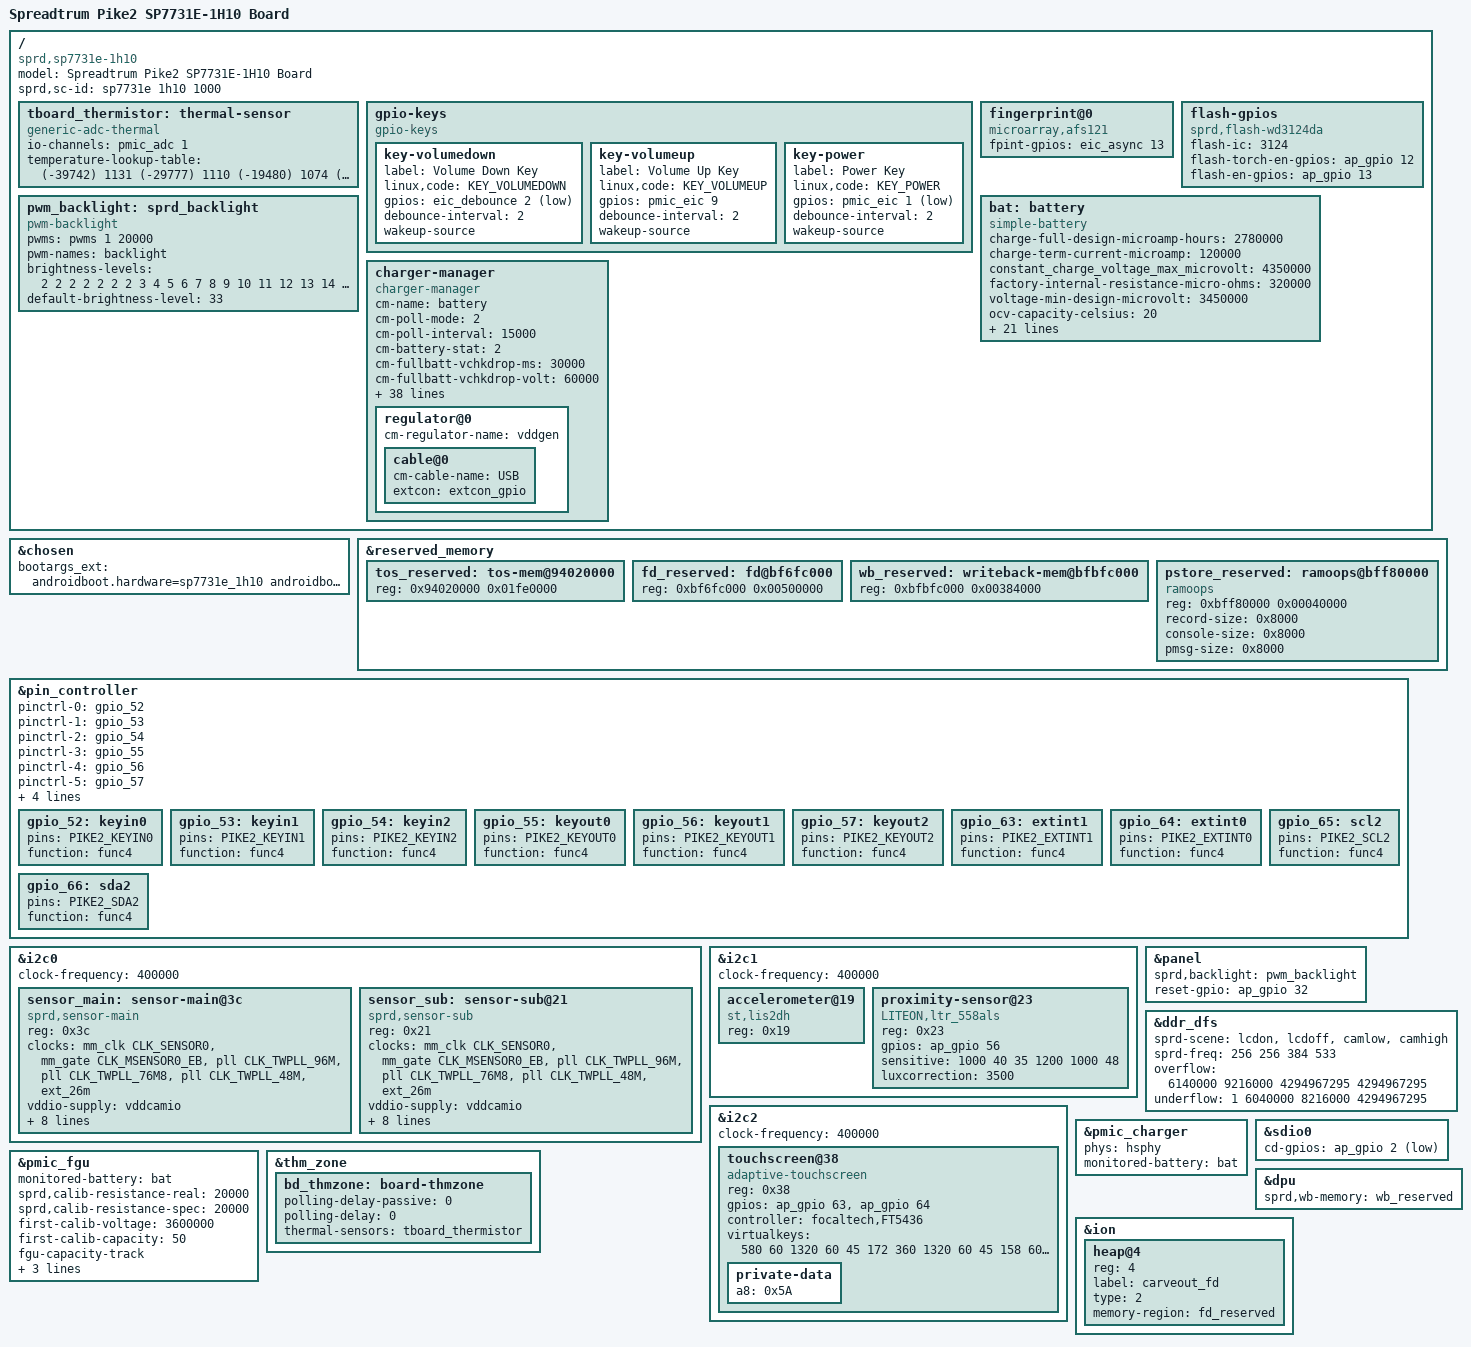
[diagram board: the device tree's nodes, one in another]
/*
 * Spreadtrum sharkle sp7731e board DTS file
 *
 * Copyright (C) 2019, Spreadtrum Communications Inc.
 *
 * This file is licensed under a dual GPLv2 or X11 license.
 */
/dts-v1/;
/plugin/;
#include <dt-bindings/input/input.h>
#include <dt-bindings/gpio/gpio.h>
#include <dt-bindings/clock/sprd,sc7731e-clk.h>
#include "lcd/lcd_ili9881c_3lane_mipi_fhd.dtsi"
#include "lcd/lcd_r61350_truly_mipi_hd_v2.dtsi"
#include "lcd/lcd_dummy_mipi.dtsi"

/ {
	model = "Spreadtrum Pike2 SP7731E-1H10 Board";

	compatible = "sprd,sp7731e-1h10", "sprd,sc7731e";

	sprd,sc-id = "sp7731e 1h10 1000";

	/*
	* When create a new node, we should use the key word __overlay__,
	* otherwise u-boot can not analyze it.
	*/
	fragment {
		target-path = "/";
		__overlay__ {

			tboard_thermistor:thermal-sensor {
				compatible = "generic-adc-thermal";
				#thermal-sensor-cells = <0>;
				io-channels = <&pmic_adc 1>;
				io-channel-names = "sensor-channel";
				temperature-lookup-table = <    (-39742) 1131
								(-29777) 1110
								(-19480) 1074
								(-4679) 983
								10110 838
								24805 654
								44922 413
								54903 316
								64895 238
								74884 178
								84883 133
								94883 100
								104880 75
								114889 57
								124872 43 >;
			};

			gpio-keys {
				compatible = "gpio-keys";

				key-volumedown {
					label = "Volume Down Key";
					linux,code = <KEY_VOLUMEDOWN>;
					gpios = <&eic_debounce 2 GPIO_ACTIVE_LOW>;
					debounce-interval = <2>;
					wakeup-source;
				};

				key-volumeup {
					label = "Volume Up Key";
					linux,code = <KEY_VOLUMEUP>;
					gpios = <&pmic_eic 9 GPIO_ACTIVE_HIGH>;
					debounce-interval = <2>;
					wakeup-source;
				};

				key-power {
					label = "Power Key";
					linux,code = <KEY_POWER>;
					gpios = <&pmic_eic 1 GPIO_ACTIVE_LOW>;
					debounce-interval = <2>;
					wakeup-source;
				};
			};

			fingerprint@0 {
				compatible = "microarray,afs121";
				fpint-gpios = <&eic_async 13 0>;
			};

			flash-gpios {
				compatible = "sprd,flash-wd3124da";
				flash-ic = <3124>;
				flash-torch-en-gpios = <&ap_gpio 12 0>;
				flash-en-gpios = <&ap_gpio 13 0>;
			};

			pwm_backlight: sprd_backlight {
				compatible = "pwm-backlight";
				pwms = <&pwms 1 20000>;
				pwm-names = "backlight";
				brightness-levels = <
								  2   2   2   2
					  2   2   2   3   4   5   6   7   8   9
					 10  11  12  13  14  15  16  17  18  19
					 20  21  22  23  24  25  26  27  28  29
					 30  31  32  33  34  35  36  37  38  39
					 40  41  42  43  44  45  46  47  48  49
					 50  51  52  53  54  55  56  57  58  59
					 60  61  62  63  64  65  66  67  68  69
					 70  71  72  73  74  75  76  77  78  79
					 80  81  82  83  84  85  86  87  88  89
					 90  91  92  93  94  95  96  97  98  99
					100 101 102 103 104 105 106 107 108 109
					110 111 112 113 114 115 116 117 118 119
					120 121 122 123 124 125 126 127 128 129
					130 131 132 133 134 135 136 137 138 139
					140 141 142 143 144 145 146 147 148 149
					150 151 152 153 154 155 156 157 158 159
					160 161 162 163 164 165 166 167 168 169
					170 171 172 173 174 175 176 177 178 179
					180 181 182 183 184 185 186 187 188 189
					190 191 192 193 194 195 196 197 198 199
					200 201 202 203 204 205 206 207 208 209
					210 211 212 213 214 215 216 217 218 219
					220 221 222 223 224 225 226 227 228 229
					230 231 232 233 234 235 236 237 238 239
					240 241 242 243 244 245 246 247 248 249
					250 251
					>;
				default-brightness-level = <33>;
			};

			bat: battery {
				compatible = "simple-battery";
				charge-full-design-microamp-hours = <2780000>;
				charge-term-current-microamp = <120000>;
				constant_charge_voltage_max_microvolt = <4350000>;
				factory-internal-resistance-micro-ohms = <320000>;
				voltage-min-design-microvolt = <3450000>;
				ocv-capacity-celsius = <20>;
				ocv-capacity-table-0 = <4330000 100>, <4249000 95>, <4189000 90>,
							<4133000 85>, <4081000 80>, <4034000 75>,
							<3991000 70>, <3953000 65>, <3910000 60>,
							<3866000 55>, <3836000 50>, <3813000 45>,
							<3795000 40>, <3782000 35>, <3774000 30>,
							<3765000 25>, <3750000 20>, <3726000 15>,
							<3687000 10>, <3658000 5>, <3400000 0>;
				voltage-temp-table = <1095000 800>, <986000 850>, <878000 900>,
							  <775000 950>, <678000 1000>, <590000 1050>,
							  <510000 1100>, <440000 1150>, <378000 1200>,
							  <324000 1250>, <278000 1300>, <238000 1350>,
							  <204000 1400>, <175000 1450>, <150000 1500>,
							  <129000 1550>, <111000 1600>, <96000 1650>;
				capacity-temp-table = <25 100>, <10 97>, <(-10) 60>;
				resistance-temp-table = <20 100>, <10 243>, <(-10) 468>;
				charge-sdp-current-microamp = <500000 500000>;
				charge-dcp-current-microamp = <1000000 1000000>;
				charge-cdp-current-microamp = <1000000 1000000>;
				charge-unknown-current-microamp = <500000 500000>;
			};

			charger-manager {
				compatible = "charger-manager";
				cm-name = "battery";
				cm-poll-mode = <2>;
				cm-poll-interval = <15000>;
				cm-battery-stat = <2>;

				cm-fullbatt-vchkdrop-ms = <30000>;
				cm-fullbatt-vchkdrop-volt = <60000>;
				cm-fullbatt-voltage = <4310000>;
				cm-fullbatt-current = <120000>;
				cm-fullbatt-capacity = <100>;

				cm-chargers = "sc2720_charger";
				cm-fuel-gauge = "sc27xx-fgu";

				/* in deci centigrade */
				cm-battery-cold = <200>;
				cm-battery-cold-in-minus;
				cm-battery-hot = <800>;
				cm-battery-temp-diff = <100>;

				/* Allow charging for 6hr */
				cm-charging-max = <18000000>;
				/* recovery charging after stop charging 45min */
				cm-discharging-max = <2700000>;

				/* drop voltage in microVolts to allow shutdown */
				cm-shutdown-voltage = <3100000>;

				/* when 99% of the time is exceeded, it will be forced to 100% */
				cm-tickle-time-out = <1500>;

				/* how much time to allow capacity change */
				cm-one-cap-time = <30>;

				cm-thermal-zone = "board-thmzone";

				/* This switch is turned on when chargerIC is charging linearly */
				cm-support-linear-charge;

				/* when the safe charging voltage is exceeded, stop charging */
				cm-charge-voltage-max = <6500000>;
				/* drop voltage in microVolts to restart charging */
				cm-charge-voltage-drop = <700000>;

				cm-dcp-jeita-temp-table = <1000 1030 0 4350000>, <1150 1180 700000 4350000>,
					<1450 1420 1000000 4350000>, <1600 1570 700000 4100000>;
				cm-sdp-jeita-temp-table = <1000 1030 0 4350000>, <1150 1180 500000 4350000>,
					<1450 1420 500000 4350000>, <1600 1570 500000 4100000>;
				cm-cdp-jeita-temp-table = <1000 1030 0 4350000>, <1150 1180 700000 4350000>,
					<1450 1420 1000000 4350000>, <1600 1570 700000 4100000>;
				cm-unknown-jeita-temp-table = <1000 1030 0 4350000>, <1150 1180 500000 4350000>,
					<1450 1420 500000 4350000>, <1600 1570 500000 4100000>;

				monitored-battery = <&bat>;


				cm-cap-remap-table = <1 2 3>, <2 3 2>, <98 99 2>, <99 100 3>;

				regulator@0 {
					cm-regulator-name = "vddgen";
					cable@0 {
						cm-cable-name = "USB";
						extcon = <&extcon_gpio>;
					};
				};
			};
		};
	};
};

&chosen {
	bootargs_ext = "androidboot.hardware=sp7731e_1h10 androidboot.dtbo_idx=0";
};

&reserved_memory {
	tos_reserved: tos-mem@94020000 {
		reg = <0x94020000 0x01fe0000>;
	};

	fd_reserved: fd@bf6fc000 {
		reg = <0xbf6fc000 0x00500000>;
	};

	wb_reserved: writeback-mem@bfbfc000 {
		reg = <0xbfbfc000 0x00384000>;
	};

	pstore_reserved: ramoops@bff80000 {
		compatible = "ramoops";
		reg = <0xbff80000 0x00040000>;
		record-size = <0x8000>;
		console-size = <0x8000>;
		pmsg-size = <0x8000>;
	};
};

&pin_controller {
	pinctrl-names =
	/* keyin0 ~ keyin2 */
	"gpio_52", "gpio_53", "gpio_54",
	/* keyout0 ~ keyout2 */
	"gpio_55", "gpio_56", "gpio_57",
	/* extint1, extint0, scl2, sda2 */
	"gpio_63", "gpio_64", "gpio_65", "gpio_66";
	pinctrl-0 = <&gpio_52>;
	pinctrl-1 = <&gpio_53>;
	pinctrl-2 = <&gpio_54>;
	pinctrl-3 = <&gpio_55>;
	pinctrl-4 = <&gpio_56>;
	pinctrl-5 = <&gpio_57>;
	pinctrl-6 = <&gpio_63>;
	pinctrl-7 = <&gpio_64>;
	pinctrl-8 = <&gpio_65>;
	pinctrl-9 = <&gpio_66>;

	gpio_52: keyin0 {
		pins = "PIKE2_KEYIN0";
		function = "func4";
	};

	gpio_53: keyin1 {
		pins = "PIKE2_KEYIN1";
		function = "func4";
	};

	gpio_54: keyin2 {
		pins = "PIKE2_KEYIN2";
		function = "func4";
	};

	gpio_55: keyout0 {
		pins = "PIKE2_KEYOUT0";
		function = "func4";
	};

	gpio_56: keyout1 {
		pins = "PIKE2_KEYOUT1";
		function = "func4";
	};

	gpio_57: keyout2 {
		pins = "PIKE2_KEYOUT2";
		function = "func4";
	};

	gpio_63: extint1 {
		pins = "PIKE2_EXTINT1";
		function = "func4";
	};

	gpio_64: extint0 {
		pins = "PIKE2_EXTINT0";
		function = "func4";
	};

	gpio_65: scl2 {
		pins = "PIKE2_SCL2";
		function = "func4";
	};

	gpio_66: sda2 {
		pins = "PIKE2_SDA2";
		function = "func4";
	};
};

&i2c0 {
	status = "okay";
	clock-frequency = <400000>;
	sensor_main: sensor-main@3c {
		compatible = "sprd,sensor-main";
		reg = <0x3c>;
		clock-names = "clk_src", "sensor_eb",
			"clk_96m", "clk_76m8",
			"clk_48m", "clk_26m";
		clocks  = <&mm_clk CLK_SENSOR0>,
			<&mm_gate CLK_MSENSOR0_EB>,
			<&pll CLK_TWPLL_96M>,
			<&pll CLK_TWPLL_76M8>,
			<&pll CLK_TWPLL_48M>,
			<&ext_26m>;
		vddio-supply = <&vddcamio>;
		vddcama-supply = <&vddcama>;
		vddcamd-supply = <&vddcamd>;
		vddcammot-supply = <&vddcammot>;
		reset-gpios = <&ap_gpio 37 0>;
		power-down-gpios = <&ap_gpio 38 0>;
		host = "dcam0";
		sprd,phyid = <0>;
		csi = <&csi0>;
	};

	sensor_sub: sensor-sub@21 {
		compatible = "sprd,sensor-sub";
		reg = <0x21>;
		clock-names = "clk_src","sensor_eb",
			"clk_96m", "clk_76m8",
			"clk_48m", "clk_26m";
		clocks = <&mm_clk CLK_SENSOR0>,
			<&mm_gate CLK_MSENSOR0_EB>,
			<&pll CLK_TWPLL_96M>,
			<&pll CLK_TWPLL_76M8>,
			<&pll CLK_TWPLL_48M>,
			<&ext_26m>;
		vddio-supply = <&vddcamio>;
		vddcama-supply = <&vddcama>;
		vddcamd-supply = <&vddcamd>;
		vddcammot-supply = <&vddcammot>;
		reset-gpios = <&ap_gpio 46 0>;
		power-down-gpios = <&ap_gpio 39 0>;
		host = "dcam0";
		sprd,phyid = <0>;
		csi = <&csi0>;
	};
};

&i2c1 {
	status = "okay";
	clock-frequency = <400000>;

	accelerometer@19 {
		compatible = "st,lis2dh", "st,lis2dh12";
		reg = <0x19>;
	};

	proximity-sensor@23 {
		compatible = "LITEON,ltr_558als";
		reg = <0x23>;
		gpios = <&ap_gpio 56 GPIO_ACTIVE_HIGH>;
		/*
		 *low sensitve(def):1500,250,220,1800,1600,1;
		 *have no sensitve=<> as def.
		 * High sensitve:1000,40,35,1200,1000,48
		 */
		sensitive = <1000 40 35
					1200 1000 48>;
		luxcorrection = <3500>;
	};
};

&i2c2 {
	status = "okay";
	clock-frequency = <400000>;
	touchscreen@38 {
		compatible = "adaptive-touchscreen";
		reg = <0x38>;
		gpios = <&ap_gpio 63 GPIO_ACTIVE_HIGH
			&ap_gpio 64 GPIO_ACTIVE_HIGH>;
		controller = "focaltech,FT5436";
		virtualkeys = <580 60 1320 60 45
			172 360 1320 60 45
			158 600 1320 60 45>;
		private-data {
			a8 = /bits/ 8 <0x5A>;
		};
	};
};

&panel {
	sprd,backlight = <&pwm_backlight>;
	reset-gpio = <&ap_gpio 32 GPIO_ACTIVE_HIGH>;
};

&ddr_dfs {
	sprd-scene = "lcdon", "lcdoff", "camlow", "camhigh";
	sprd-freq = <256 256 384 533>;
	overflow = <6140000 9216000 4294967295 4294967295>;
	underflow = <1 6040000 8216000 4294967295>;
};

&pmic_charger {
	status = "okay";
	phys = <&hsphy>;
	monitored-battery = <&bat>;
};

&pmic_fgu {
	monitored-battery = <&bat>;
	sprd,calib-resistance-real = <20000>;
	sprd,calib-resistance-spec = <20000>;
	first-calib-voltage = <3600000>;
	first-calib-capacity = <50>;
	fgu-capacity-track;
	fullbatt-track-end-vol = <4305>;
	fullbatt-track-end-cur = <130>;
	phys = <&hsphy>;
};

&sdio0 {
	cd-gpios = <&ap_gpio 2 1>;
};

&thm_zone {
	bd_thmzone: board-thmzone {
		polling-delay-passive = <0>;
		polling-delay = <0>;
		thermal-sensors = <&tboard_thermistor>;
	};
};

&dpu {
	status = "okay";
	sprd,wb-memory = <&wb_reserved>;
};

&ion {
	heap@4 {
		reg = <4>;
		label = "carveout_fd";
		type = <2>;
		memory-region = <&fd_reserved>;
	};
};
